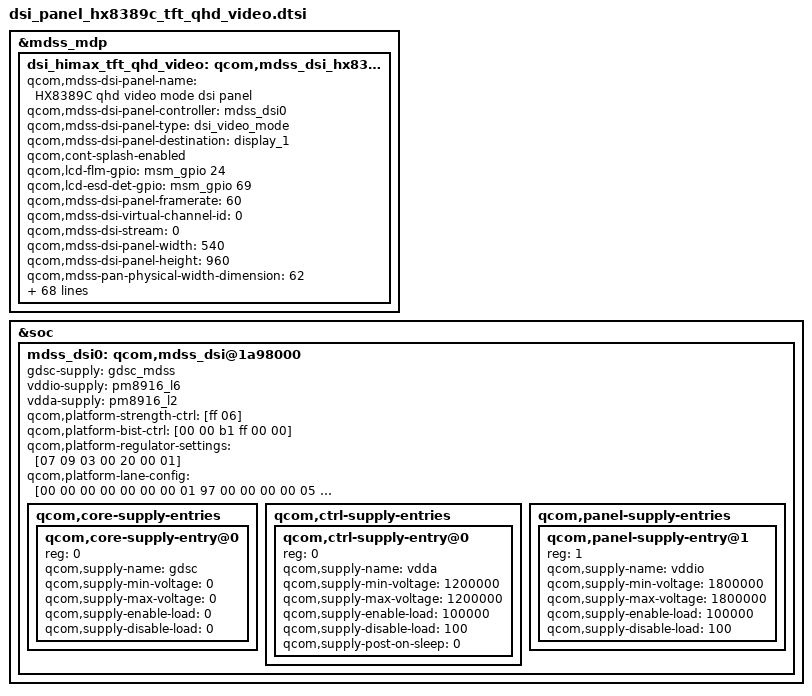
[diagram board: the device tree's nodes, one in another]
/* Copyright (c) 2013-14, Samsung Electronics Corporation. All rights reserved.
 *
 * This program is free software; you can redistribute it and/or modify
 * it under the terms of the GNU General Public License version 2 and
 * only version 2 as published by the Free Software Foundation.
 *
 * This program is distributed in the hope that it will be useful,
 * but WITHOUT ANY WARRANTY; without even the implied warranty of
 * MERCHANTABILITY or FITNESS FOR A PARTICULAR PURPOSE.  See the
 * GNU General Public License for more details.
 */

/*---------------------------------------------------------------------------
 * This file is autogenerated file using gcdb parser. Please do not edit it.
 * Update input XML file to add a new entry or update variable in this file
 * VERSION = "1.0"
 *---------------------------------------------------------------------------

 */
&mdss_mdp {
	dsi_himax_tft_qhd_video: qcom,mdss_dsi_hx8389c_qhd_video {
		qcom,mdss-dsi-panel-name = "HX8389C qhd video mode dsi panel";
		qcom,mdss-dsi-panel-controller = <&mdss_dsi0>;
		qcom,mdss-dsi-panel-type = "dsi_video_mode";
		qcom,mdss-dsi-panel-destination = "display_1";
		qcom,cont-splash-enabled;
		qcom,lcd-flm-gpio = <&msm_gpio 24 0>;
		qcom,lcd-esd-det-gpio = <&msm_gpio 69 0>;
		qcom,mdss-dsi-panel-framerate = <60>;
		qcom,mdss-dsi-virtual-channel-id = <0>;
		qcom,mdss-dsi-stream = <0>;
		qcom,mdss-dsi-panel-width = <540>;
		qcom,mdss-dsi-panel-height = <960>;
              qcom,mdss-pan-physical-width-dimension = <62>; /* <Width> real size of panel in mm */
		qcom,mdss-pan-physical-height-dimension = <110>; /*<Height> real size of panel in mm */
		qcom,mdss-dsi-lp11-init;
		qcom,mdss-dsi-init-delay-us = <100>;
		qcom,mdss-dsi-h-front-porch = <10>;
		qcom,mdss-dsi-h-back-porch = <10>;
		qcom,mdss-dsi-h-pulse-width = <14>;
		qcom,mdss-dsi-h-front-porch-3g = <20>;
		qcom,mdss-dsi-h-back-porch-3g = <20>;
		qcom,mdss-dsi-h-pulse-width-3g = <18>;
		qcom,mdss-dsi-h-front-porch-boe = <10>;
		qcom,mdss-dsi-h-back-porch-boe = <10>;
		qcom,mdss-dsi-h-pulse-width-boe = <14>;
		qcom,mdss-dsi-h-sync-skew = <0>;
		qcom,mdss-dsi-v-back-porch = <5>;
		qcom,mdss-dsi-v-front-porch = <9>;
		qcom,mdss-dsi-v-back-porch-boe = <6>;
		qcom,mdss-dsi-v-front-porch-boe = <8>;
		qcom,mdss-dsi-v-pulse-width = <2>;
		qcom,mdss-dsi-h-left-border = <0>;
		qcom,mdss-dsi-h-right-border = <0>;
		qcom,mdss-dsi-v-top-border = <0>;
		qcom,mdss-dsi-v-bottom-border = <0>;
		qcom,mdss-dsi-bpp = <24>;
		qcom,mdss-dsi-color-order = <0>;
		qcom,mdss-dsi-underflow-color = <0xff>;
		qcom,mdss-dsi-border-color = <0>;
		qcom,mdss-dsi-dma-trigger = "trigger_sw";
		qcom,mdss-dsi-mdp-trigger = "none";
		qcom,mdss-dsi-bl-min-level = <1>;
		qcom,mdss-dsi-bl-max-level = <255>;
		/* Overridden in board device tree as this functionality changes between hardware revision */
		qcom,mdss-dsi-bl-pmic-control-type = "bl_ctrl_gpio_swing";
		qcom,mdss-dsi-lane-0-state;
		qcom,mdss-dsi-lane-1-state;
		qcom,mdss-dsi-bllp-eof-power-mode;
		qcom,mdss-dsi-bllp-power-mode;
		qcom,mdss-dsi-traffic-mode = "non_burst_sync_pulse";
		qcom,mdss-force-clk-lane-hs = <0>;
		qcom,mdss-dsi-reset-sequence = <1 10>, <0 2>, <1 80>;
		qcom,mdss-dsi-reset-sequence-boe = <1 10>, <0 5>, <1 30>;
		qcom,mdss-dsi-lane-map = <0>;
		qcom,mdss-dsi-h-sync-pulse = <0>;
              qcom,mdss-dsi-panel-timings = [81 1C 12 00 40 44 16 1E 23 03 04 00];
              qcom,mdss-dsi-t-clk-pre = <0x18>;
		qcom,mdss-dsi-t-clk-post = <0x04>;
		qcom,mdss-dsi-on-command = [39 01 00 00 0A 00 04 B9 FF 83 89
				39 01 00 00 00 00 15 B1 7F 10 10 D2 32 80 10 F0 56 80 20 20 F8 AA AA A1 00 80 30 00
				39 01 00 00 00 00 0B B2 82 50 05 07 F0 38 11 64 5D 09
				39 01 00 00 00 00 0C B4 66 66 66 70 00 00 18 76 28 76 A8
				39 01 00 00 00 00 02 D2 33
				39 01 00 00 00 00 05 C0 30 17 00 03
				39 01 00 00 00 00 05 C7 00 80 00 C0
				39 01 00 00 0A 00 05 BF 05 50 00 3E
				39 01 00 00 00 00 04 B9 FF 83 89
				39 01 00 00 00 00 02 CC 0E
				39 01 00 00 00 00 24 D3 00 00 00 00 00 08 00 32 10 00 00 00 03 C6 03 C6 00 00 00 00 35 33 04 04 37 00 00 00 05 08 00 00 0A 00 01
				39 01 00 00 00 00 27 D5 18 18 18 18 19 19 18 18 20 21 24 25 18 18 18 18 00 01 04 05 02 03 06 07 18 18 18 18 18 18 18 18 18 18 18 18 18 18
				39 01 00 00 00 00 27 D6 18 18 18 18 18 18 19 19 25 24 21 20 18 18 18 18 07 06 03 02 05 04 01 00 18 18 18 18 18 18 18 18 18 18 18 18 18 18
				39 01 00 00 00 00 04 B7 20 80 00
				39 01 00 00 00 00 2B E0 00 02 06 38 3C 3F 1B 46 06 09 0C 17 10 13 16 13 14 08 13 15 19 00 02 06 37 3C 3F 1A 45 05 09 0B 16 0F 13 15 13 14 07 12 14 18
				39 01 00 00 00 00 02 BD 00
				39 01 00 00 00 00 2C C1 00 00 08 10 18 20 28 30 38 40 48 50 58 60 68 70 78 80 88 90 98 A0 A8 B0 B8 C0 C8 D0 D8 E0 E8 F0 F8 FF 00 00 00 00 00 00 00 00 00
				39 01 00 00 00 00 02 BD 01
				39 01 00 00 00 00 2B C1 00 08 10 18 20 28 30 38 40 48 50 58 60 68 70 78 80 88 90 98 A0 A8 B0 B8 C0 C8 D0 D8 E0 E8 F0 F8 FF 00 00 00 00 00 00 00 00 00
				39 01 00 00 00 00 02 BD 02
				39 01 00 00 00 00 2B C1 00 08 10 18 20 28 30 38 40 48 50 58 60 68 70 78 80 88 90 98 A0 A8 B0 B8 C0 C8 D0 D8 E0 E8 F0 F8 FF 00 00 00 00 00 00 00 00 00
				/*CABC Begin*/
				39 01 00 00 05 00 0E C9 1F 00 0F 1E 81 1E 00 00 01 19 00 00 20  /* CABC PWM output to 25Khz*/
				39 01 00 00 05 00 02 55 00			/*Turn off CABC*/
				39 01 00 00 05 00 02 53 24 /*Enable Backlight Control */
				/* CABC end*/
				05 01 00 00 7D 00 02 11 00
				05 01 00 00 05 00 02 29 00
					];
		qcom,mdss-dsi-off-command = [
						/* < Deep Sleep In Sequence > */
						39 01 00 00 3C 00 02 28 00
						39 01 00 00 3C 00 02 10 00
					];
		qcom,mdss-dsi-on-command-boe = [				/* Initializing Sequennce(1) */
				39 01 00 00 00 00 03 F0 5A 5A
				39 01 00 00 00 00 03 F1 5A 5A
				39 01 00 00 00 00 03 FC A5 A5
				05 01 00 00 78 00 02 11 00
				/* Initializing Sequennce(2) */
				39 01 00 00 00 00 02 B1 93	// Internal CLK
				39 01 00 00 00 00 02 B5 10	// Panel Protection
				39 01 00 00 00 00 12 F4 01 10 32 00 24 26 28 27 27 27 B7 2B 2C 65 6A 34 20	// 18 ea, Internal Power Sequence
				39 01 00 00 00 00 15 EF 01 01 81 22 83 04 00 00 00 00 28 81 00 21 21 03 03 40 00 10	// 21 ea, GOA Timing
				39 01 00 00 00 00 09 F2 19 04 08 08 08 14 14 00	// Internal Porch
				39 01 00 00 00 00 07 F6 93 23 15 07 07 0C	// Source Control
				39 01 00 00 00 00 07 E1 01 FF 01 1B 20 17	// MIPI Abnormal Detect
				39 01 00 00 00 00 04 E2 ED C7 23	// MIPI Auto Recover
				39 01 00 00 00 00 27 F7 01 01 0A 0B 05 1B 1A 01 01 01 01 01 01 01 01 01 01 01 01 01 01 08 09 04 1B 1A 01 01 01 01 01 01 01 01 01 01 01 01	// 39, GOA Output
				39 01 00 00 00 00 02 36 10	// Memory Data Access Control
				39 01 00 00 00 00 28 FA 00 19 21 1E 14 0B 10 0E 09 0B 00 00 0A 00 1D 21 1E 14 0B 10 0E 09 0B 00 00 0A 00 1C 21 1E 14 0B 10 0E 09 0B 00 00 0A // 40, Positive Gamma Control
				39 01 00 00 00 00 28 FB 07 2D 22 24 18 0E 11 0C 05 05 00 00 0A 00 29 22 24 18 0E 11 0C 05 05 00 00 0A 07 2A 22 24 18 0E 11 0C 05 05 00 00 0A //Negative Gamma Control
				05 01 00 00 14 00 02 29 00
				39 01 00 00 00 00 03 F0 A5 A5
				39 01 00 00 00 00 03 F1 A5 A5
				39 01 00 00 00 00 03 FC 5A 5A
				];
		qcom,mdss-dsi-off-command-boe = [
				/* < Deep Sleep In Sequence > */
				39 01 00 00 0A 00 02 28 00
				39 01 00 00 78 00 02 10 00
					];
		samsung,panel-manufacture-id-read-cmds = [06 01 00 00 00 00 01 da 01
							06 01 00 00 00 00 01 db 01
							06 01 00 00 00 00 01 dc 01];
		/*
		 * Command sets for CABC control
		 */
		samsung,cabc-on-ui-cmds= [
				39 01 00 00 05 00 02 55 01 /* CABC UI MODE , delay 5ms*/
				39 01 00 00 05 00 02 53 24 /*Enable Backlight Control */
		];
		samsung,cabc-on-still-cmds= [
				39 01 00 00 05 00 02 55 02 /* CABC STILL MODE , delay 5ms*/
				39 01 00 00 05 00 02 53 24 /*Enable Backlight Control */
		];
		samsung,cabc-on-moving-cmds= [
				39 01 00 00 05 00 02 55 03 /* CABC Moving MODE , delay 5ms*/
				39 01 00 00 05 00 02 53 24 /*Enable Backlight Control */
		];
		samsung,cabc-off-cmds = [
			39 01 00 00 05 00 02 55 00			/*Turn off CABC*/
		];

		qcom,mdss-dsi-on-command-state = "dsi_lp_mode";
		qcom,mdss-dsi-off-command-state = "dsi_hs_mode";
	};
};
&soc {
	mdss_dsi0: qcom,mdss_dsi@1a98000 {
		gdsc-supply = <&gdsc_mdss>;
		vddio-supply = <&pm8916_l6>;
		vdda-supply = <&pm8916_l2>;
		qcom,platform-strength-ctrl = [ff 06];
		qcom,platform-bist-ctrl = [00 00 b1 ff 00 00];
		qcom,platform-regulator-settings = [07 09 03 00 20 00 01];
		qcom,platform-lane-config = [00 00 00 00 00 00 00 01 97
			00 00 00 00 05 00 00 01 97
			00 00 00 00 0a 00 00 01 97
			00 00 00 00 0f 00 00 01 97
			00 c0 00 00 00 00 00 01 bb];
		qcom,core-supply-entries {
			#address-cells = <1>;
			#size-cells = <0>;

			qcom,core-supply-entry@0 {
				reg = <0>;
				qcom,supply-name = "gdsc";
				qcom,supply-min-voltage = <0>;
				qcom,supply-max-voltage = <0>;
				qcom,supply-enable-load = <0>;
				qcom,supply-disable-load = <0>;
			};
		};
		qcom,ctrl-supply-entries {
			#address-cells = <1>;
			#size-cells = <0>;

			qcom,ctrl-supply-entry@0 {
				reg = <0>;
				qcom,supply-name = "vdda";
				qcom,supply-min-voltage = <1200000>;
				qcom,supply-max-voltage = <1200000>;
				qcom,supply-enable-load = <100000>;
				qcom,supply-disable-load = <100>;
				qcom,supply-post-on-sleep = <0>;
			};
		};
		qcom,panel-supply-entries {
			#address-cells = <1>;
			#size-cells = <0>;

			qcom,panel-supply-entry@1 {
				reg = <1>;
				qcom,supply-name = "vddio";
				qcom,supply-min-voltage = <1800000>;
				qcom,supply-max-voltage = <1800000>;
				qcom,supply-enable-load = <100000>;
				qcom,supply-disable-load = <100>;
			};
		};
	};
};

